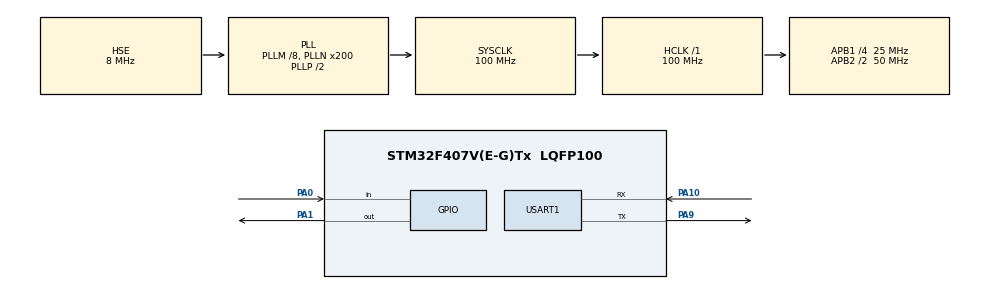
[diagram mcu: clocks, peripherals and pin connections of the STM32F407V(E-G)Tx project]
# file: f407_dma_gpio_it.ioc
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Dma.MEMTOMEM.0.Direction=DMA_MEMORY_TO_MEMORY
Dma.MEMTOMEM.0.FIFOMode=DMA_FIFOMODE_ENABLE
Dma.MEMTOMEM.0.FIFOThreshold=DMA_FIFO_THRESHOLD_FULL
Dma.MEMTOMEM.0.Instance=DMA2_Stream0
Dma.MEMTOMEM.0.MemBurst=DMA_MBURST_SINGLE
Dma.MEMTOMEM.0.MemDataAlignment=DMA_MDATAALIGN_BYTE
Dma.MEMTOMEM.0.MemInc=DMA_MINC_DISABLE
Dma.MEMTOMEM.0.Mode=DMA_NORMAL
Dma.MEMTOMEM.0.PeriphBurst=DMA_PBURST_SINGLE
Dma.MEMTOMEM.0.PeriphDataAlignment=DMA_PDATAALIGN_BYTE
Dma.MEMTOMEM.0.PeriphInc=DMA_PINC_DISABLE
Dma.MEMTOMEM.0.Priority=DMA_PRIORITY_LOW
Dma.Request0=MEMTOMEM
Mcu.Family=STM32F4
Mcu.Name=STM32F407V(E-G)Tx
Mcu.Package=LQFP100
NVIC.DMA2_Stream0_IRQn=true\:0\:0\:false\:false\:true\:true\:true
NVIC.PriorityGroup=NVIC_PRIORITYGROUP_4
PA0-WKUP.Signal=GPIO_Input
PA1.Signal=GPIO_Output
PA10.Mode=Asynchronous
PA10.Signal=USART1_RX
PA13.Mode=Serial_Wire
PA13.Signal=SYS_JTMS-SWDIO
PA14.Mode=Serial_Wire
PA14.Signal=SYS_JTCK-SWCLK
PA9.Mode=Asynchronous
PA9.Signal=USART1_TX
PH0-OSC_IN.Mode=HSE-External-Oscillator
PH0-OSC_IN.Signal=RCC_OSC_IN
PH1-OSC_OUT.Mode=HSE-External-Oscillator
PH1-OSC_OUT.Signal=RCC_OSC_OUT
ProjectManager.HeapSize=0x200
ProjectManager.StackSize=0x400
ProjectManager.TargetToolchain=STM32CubeIDE
RCC.48MHZClocksFreq_Value=50000000
RCC.AHBFreq_Value=100000000
RCC.APB1CLKDivider=RCC_HCLK_DIV4
RCC.APB1Freq_Value=25000000
RCC.APB1TimFreq_Value=50000000
RCC.APB2CLKDivider=RCC_HCLK_DIV2
RCC.APB2Freq_Value=50000000
RCC.APB2TimFreq_Value=100000000
RCC.CortexFreq_Value=100000000
RCC.HCLKFreq_Value=100000000
RCC.HSE_VALUE=8000000
RCC.HSI_VALUE=16000000
RCC.LSE_VALUE=32768
RCC.PLLM=8
RCC.PLLN=200
RCC.PLLSourceVirtual=RCC_PLLSOURCE_HSE
RCC.SYSCLKFreq_VALUE=100000000
RCC.SYSCLKSource=RCC_SYSCLKSOURCE_PLLCLK
RCC.VCOOutputFreq_Value=200000000
USART1.VirtualMode=VM_ASYNC
board=custom

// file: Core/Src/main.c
/* USER CODE BEGIN Header */
// DevEBox STM32F407VGT6 dev board
// Demo DMA transfer of data from SRAM1 to gpio port
// in this case 0x00 and 0xFF sent to a pin with led
// to make it flash periodically

/* USER CODE END Header */

#include "main.h"

UART_HandleTypeDef huart1;

DMA_HandleTypeDef hdma_memtomem_dma2_stream0;

void SystemClock_Config(void);
static void MX_GPIO_Init(void);
static void MX_DMA_Init(void);
static void MX_USART1_UART_Init(void);
/* USER CODE BEGIN PFP */
void dmaCompleteCallback(DMA_HandleTypeDef* hdma);
/* USER CODE END PFP */

/* USER CODE BEGIN 0 */

uint8_t ledData[2] = {0x00, 0xFF};
/* USER CODE END 0 */

int main(void)
{

  /* MCU Configuration--------------------------------------------------------*/

  /* Reset of all peripherals, Initializes the Flash interface and the Systick. */
  HAL_Init();

  /* Configure the system clock */
  SystemClock_Config();

  /* Initialize all configured peripherals */
  MX_GPIO_Init();
  MX_DMA_Init();
  MX_USART1_UART_Init();
  /* USER CODE BEGIN 2 */
  HAL_DMA_RegisterCallback(&hdma_memtomem_dma2_stream0, HAL_DMA_XFER_CPLT_CB_ID, dmaCompleteCallback);
  /* USER CODE END 2 */

  /* Infinite loop */
  while (1)
  {

    /* USER CODE BEGIN 3 */
	  if (HAL_OK != HAL_DMA_Start_IT(&hdma_memtomem_dma2_stream0, (uint32_t)&ledData[0], (uint32_t)&GPIOA->ODR,1)) {
		  Error_Handler();
	  	  }
	  HAL_Delay(100);
	  if (HAL_OK != HAL_DMA_Start_IT(&hdma_memtomem_dma2_stream0, (uint32_t)&ledData[1], (uint32_t)&GPIOA->ODR,1)) {
		  Error_Handler();
	  	  }
	  HAL_Delay(100);
  }
  /* USER CODE END 3 */
}

void SystemClock_Config(void)
{
  RCC_OscInitTypeDef RCC_OscInitStruct = {0};
  RCC_ClkInitTypeDef RCC_ClkInitStruct = {0};

  /** Configure the main internal regulator output voltage
  */
  __HAL_RCC_PWR_CLK_ENABLE();
  __HAL_PWR_VOLTAGESCALING_CONFIG(PWR_REGULATOR_VOLTAGE_SCALE1);
  /** Initializes the CPU, AHB and APB busses clocks
  */
  RCC_OscInitStruct.OscillatorType = RCC_OSCILLATORTYPE_HSE;
  RCC_OscInitStruct.HSEState = RCC_HSE_ON;
  RCC_OscInitStruct.PLL.PLLState = RCC_PLL_ON;
  RCC_OscInitStruct.PLL.PLLSource = RCC_PLLSOURCE_HSE;
  RCC_OscInitStruct.PLL.PLLM = 8;
  RCC_OscInitStruct.PLL.PLLN = 200;
  RCC_OscInitStruct.PLL.PLLP = RCC_PLLP_DIV2;
  RCC_OscInitStruct.PLL.PLLQ = 4;
  if (HAL_RCC_OscConfig(&RCC_OscInitStruct) != HAL_OK)
  {
    Error_Handler();
  }
  /** Initializes the CPU, AHB and APB busses clocks
  */
  RCC_ClkInitStruct.ClockType = RCC_CLOCKTYPE_HCLK|RCC_CLOCKTYPE_SYSCLK
                              |RCC_CLOCKTYPE_PCLK1|RCC_CLOCKTYPE_PCLK2;
  RCC_ClkInitStruct.SYSCLKSource = RCC_SYSCLKSOURCE_PLLCLK;
  RCC_ClkInitStruct.AHBCLKDivider = RCC_SYSCLK_DIV1;
  RCC_ClkInitStruct.APB1CLKDivider = RCC_HCLK_DIV4;
  RCC_ClkInitStruct.APB2CLKDivider = RCC_HCLK_DIV2;

  if (HAL_RCC_ClockConfig(&RCC_ClkInitStruct, FLASH_LATENCY_3) != HAL_OK)
  {
    Error_Handler();
  }
}

static void MX_USART1_UART_Init(void)
{

  huart1.Instance = USART1;
  huart1.Init.BaudRate = 115200;
  huart1.Init.WordLength = UART_WORDLENGTH_8B;
  huart1.Init.StopBits = UART_STOPBITS_1;
  huart1.Init.Parity = UART_PARITY_NONE;
  huart1.Init.Mode = UART_MODE_TX_RX;
  huart1.Init.HwFlowCtl = UART_HWCONTROL_NONE;
  huart1.Init.OverSampling = UART_OVERSAMPLING_16;
  if (HAL_UART_Init(&huart1) != HAL_OK)
  {
    Error_Handler();
  }

}

static void MX_DMA_Init(void)
{

  /* DMA controller clock enable */
  __HAL_RCC_DMA2_CLK_ENABLE();

  /* Configure DMA request hdma_memtomem_dma2_stream0 on DMA2_Stream0 */
  hdma_memtomem_dma2_stream0.Instance = DMA2_Stream0;
  hdma_memtomem_dma2_stream0.Init.Channel = DMA_CHANNEL_0;
  hdma_memtomem_dma2_stream0.Init.Direction = DMA_MEMORY_TO_MEMORY;
  hdma_memtomem_dma2_stream0.Init.PeriphInc = DMA_PINC_DISABLE;
  hdma_memtomem_dma2_stream0.Init.MemInc = DMA_MINC_DISABLE;
  hdma_memtomem_dma2_stream0.Init.PeriphDataAlignment = DMA_PDATAALIGN_BYTE;
  hdma_memtomem_dma2_stream0.Init.MemDataAlignment = DMA_MDATAALIGN_BYTE;
  hdma_memtomem_dma2_stream0.Init.Mode = DMA_NORMAL;
  hdma_memtomem_dma2_stream0.Init.Priority = DMA_PRIORITY_LOW;
  hdma_memtomem_dma2_stream0.Init.FIFOMode = DMA_FIFOMODE_ENABLE;
  hdma_memtomem_dma2_stream0.Init.FIFOThreshold = DMA_FIFO_THRESHOLD_FULL;
  hdma_memtomem_dma2_stream0.Init.MemBurst = DMA_MBURST_SINGLE;
  hdma_memtomem_dma2_stream0.Init.PeriphBurst = DMA_PBURST_SINGLE;
  if (HAL_DMA_Init(&hdma_memtomem_dma2_stream0) != HAL_OK)
  {
    Error_Handler( );
  }

  /* DMA interrupt init */
  /* DMA2_Stream0_IRQn interrupt configuration */
  HAL_NVIC_SetPriority(DMA2_Stream0_IRQn, 0, 0);
  HAL_NVIC_EnableIRQ(DMA2_Stream0_IRQn);

}

static void MX_GPIO_Init(void)
{
  GPIO_InitTypeDef GPIO_InitStruct = {0};

  /* GPIO Ports Clock Enable */
  __HAL_RCC_GPIOH_CLK_ENABLE();
  __HAL_RCC_GPIOA_CLK_ENABLE();

  /*Configure GPIO pin Output Level */
  HAL_GPIO_WritePin(GPIOA, GPIO_PIN_1, GPIO_PIN_RESET);

  /*Configure GPIO pin : PA0 */
  GPIO_InitStruct.Pin = GPIO_PIN_0;
  GPIO_InitStruct.Mode = GPIO_MODE_INPUT;
  GPIO_InitStruct.Pull = GPIO_NOPULL;
  HAL_GPIO_Init(GPIOA, &GPIO_InitStruct);

  /*Configure GPIO pin : PA1 */
  GPIO_InitStruct.Pin = GPIO_PIN_1;
  GPIO_InitStruct.Mode = GPIO_MODE_OUTPUT_PP;
  GPIO_InitStruct.Pull = GPIO_NOPULL;
  GPIO_InitStruct.Speed = GPIO_SPEED_FREQ_LOW;
  HAL_GPIO_Init(GPIOA, &GPIO_InitStruct);

}

/* USER CODE BEGIN 4 */
// this is running in interrupt context so should be minimal
void dmaCompleteCallback(DMA_HandleTypeDef* hdma){

}

/* USER CODE END 4 */

void Error_Handler(void)
{
  /* USER CODE BEGIN Error_Handler_Debug */
  /* User can add his own implementation to report the HAL error return state */
	int counter = 0;
	while (1) {
		HAL_GPIO_TogglePin(GPIOA, GPIO_PIN_1);
		while (counter < 0x3FFFF) {counter++;}
		counter = 0;
		}
  /* USER CODE END Error_Handler_Debug */
}

/************************ (C) COPYRIGHT STMicroelectronics *****END OF FILE****/
